# CH583SFR register map
Vendor: WCH Ltd.; Series: CH58x; File version: 1.1
CPU: RISC-V r0p0, little endian, no MPU, no FPU, 2 interrupt priority bits
Registers are 8-bit, read-write, reset 0x0 unless marked. A register's access mark holds for its fields unless they carry their own. Offsets are from the block's base; [hi:lo] are bit positions.

## GPIOB — System Control Register
Base 0x40001000
0x92 INT_EN 16-bit — RW, GPIO PB interrupt enable
  [15:0] INT_EN — GPIO PB interrupt enable
0x96 INT_MODE 16-bit — RW, GPIO PB interrupt mode: 0=level action, 1=edge action
  [15:0] INT_MODE — GPIO PB interrupt mode
0x9E INT_IF 16-bit — RW1, GPIO PB interrupt flag
  [15:0] INT_IF — GPIO PB interrupt flag
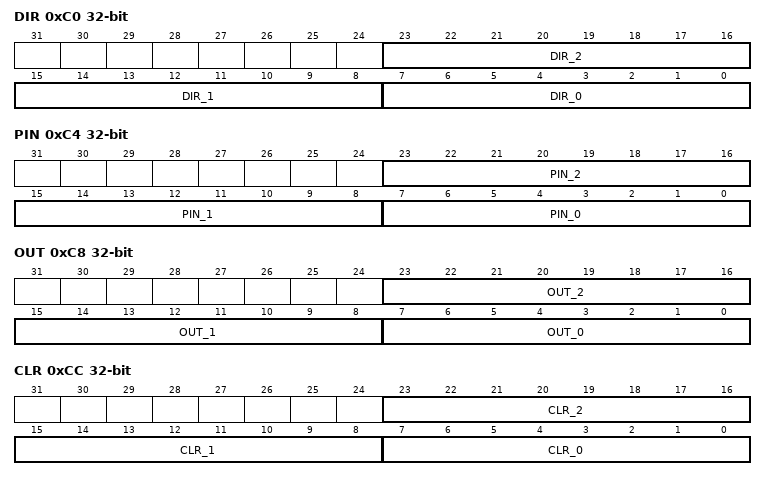
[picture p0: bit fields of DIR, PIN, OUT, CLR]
0xC0 DIR 32-bit — RW, GPIO PB I/O direction: 0=in, 1=out
  [23:16] DIR_2 — GPIO PB I/O direction byte 2
  [15:8] DIR_1 — GPIO PB I/O direction byte 1
  [7:0] DIR_0 — GPIO PB I/O direction byte 0
0xC4 PIN 32-bit ro — RO, GPIO PB input
  [23:16] PIN_2 — GPIO PB input byte 2
  [15:8] PIN_1 — GPIO PB input byte 1
  [7:0] PIN_0 — GPIO PB input byte 0
0xC8 OUT 32-bit — RW, GPIO PB output
  [23:16] OUT_2 — GPIO PB output byte 2
  [15:8] OUT_1 — GPIO PB output byte 1
  [7:0] OUT_0 — GPIO PB output byte 0
0xCC CLR 32-bit — WZ, GPIO PB clear output: 0=keep, 1=clear
  [23:16] CLR_2 — GPIO PB clear output byte 2
  [15:8] CLR_1 — GPIO PB clear output byte 1
  [7:0] CLR_0 — GPIO PB clear output byte 0
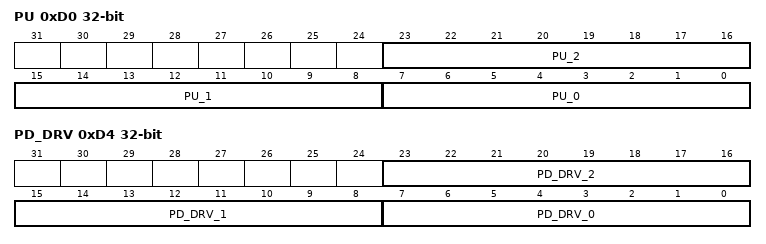
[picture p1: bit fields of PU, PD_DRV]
0xD0 PU 32-bit — RW, GPIO PB pullup resistance enable
  [23:16] PU_2 — GPIO PB pullup resistance enable byte 2
  [15:8] PU_1 — GPIO PB pullup resistance enable byte 1
  [7:0] PU_0 — GPIO PB pullup resistance enable byte 0
0xD4 PD_DRV 32-bit — RW, PB pulldown for input or PB driving capability for output
  [23:16] PD_DRV_2 — PB pulldown for input or PB driving capability for output byte 0
  [15:8] PD_DRV_1 — PB pulldown for input or PB driving capability for output byte 0
  [7:0] PD_DRV_0 — PB pulldown for input or PB driving capability for output byte 0

## TMR0 — Timer0 register
Base 0x40002000
0x00 CTRL_MOD reset 0x2 — RW, TMR0 mode control
  [7:6] PWM_REPEAT — RW, timer PWM repeat mode: 00=1, 01=4, 10=8, 11-16
  [7:6] CAP_EDGE — RW, timer capture edge mode: 00=disable, 01=edge change, 10=fall to fall, 11-rise to rise
  [4] OUT_POLAR — RW, timer PWM output polarity: 0=default low and high action, 1=default high and low action
  [4] CAP_COUNT — RW, count sub-mode if RB_TMR_MODE_IN=1: 0=capture, 1=count
  [3] OUT_EN — RW, timer output enable
  [2] COUNT_EN — RW, timer count enable
  [1] ALL_CLEAR — RW, force clear timer FIFO and count
  [0] MODE_IN — RW, timer in mode: 0=timer/PWM, 1=capture/count
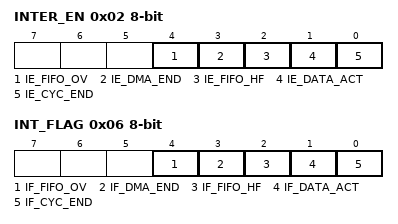
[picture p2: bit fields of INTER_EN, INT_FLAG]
0x02 INTER_EN — RW, TMR0 interrupt enable
  [4] IE_FIFO_OV — RW, enable interrupt for timer FIFO overflow
  [3] IE_DMA_END — RW, enable interrupt for timer1/2 DMA completion
  [2] IE_FIFO_HF — RW, enable interrupt for timer FIFO half (capture fifo >=4 or PWM fifo less than 3)
  [1] IE_DATA_ACT — RW, enable interrupt for timer capture input action or PWM trigger
  [0] IE_CYC_END — RW, enable interrupt for timer capture count timeout or PWM cycle end
0x06 INT_FLAG — RW1, TMR0 interrupt flag
  [4] IF_FIFO_OV — RW1, interrupt flag for timer FIFO overflow
  [3] IF_DMA_END — RW1, interrupt flag for timer1/2 DMA completion
  [2] IF_FIFO_HF — RW1, interrupt flag for timer FIFO half (capture fifo >=4 or PWM fifo less than 3
  [1] IF_DATA_ACT — RW1, interrupt flag for timer capture input action or PWM trigger
  [0] IF_CYC_END — RW1, interrupt flag for timer capture count timeout or PWM cycle end
0x07 FIFO_COUNT ro (reset mask 0xF0) — RO, TMR0 FIFO count status
  [7:0] FIFO_COUNT — RW1,TMR0 FIFO count status
0x08 COUNT 32-bit ro — RO, TMR0 current count
  [31:0] COUNT — RW1,TMR0 current count
0x0C CNT_END 32-bit — RW, TMR0 end count value, only low 26 bit
  [31:0] CNT_END — RW1,TMR0 end count value
0x10 FIFO 32-bit ro — RO/WO, TMR0 FIFO register, only low 26 bit
  [31:0] FIFO — RW1,TMR0 FIFO register

## TMR1 — Timer1 register
Base 0x40002400
Registers as TMR0 (with TMR0 read as TMR1); these are added or differ:
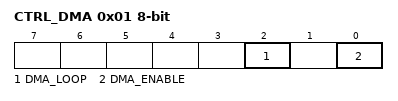
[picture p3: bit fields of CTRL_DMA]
0x01 CTRL_DMA — RW, TMR1 DMA control
  [2] DMA_LOOP — RW, timer1/2 DMA address loop enable
  [0] DMA_ENABLE — RW, timer1/2 DMA enable
0x07 FIFO_COUNT ro (reset mask 0xF0) — RO, TMR1 FIFO count status
  [7:0] FIFO_COUNT — RW1, TMR1 FIFO count status
0x0C CNT_END 32-bit — RW, TMR1 end count value, only low 26 bit
  [31:0] CNT_END — RW1,TMR1 end count value,
0x10 FIFO 32-bit ro — RO, TMR1 FIFO register, only low 26 bit
  [31:0] FIFO — RW1,TMR1 FIFO register
0x14 DMA_NOW 16-bit ro — RO, TMR1 DMA current address
  [15:0] DMA_NOW — RW1,TMR1 FIFO register
0x18 DMA_BEG 16-bit — RW, TMR1 DMA begin address
  [15:0] DMA_BEG — RW1,TMR1 FIFO register
0x1C DMA_END 16-bit — RW, TMR1 DMA end address
  [15:0] DMA_END — RW1,TMR1 FIFO register

## TMR3 — Timer3 register
Base 0x40002C00
Registers as TMR0 (with TMR0 read as TMR3); these are added or differ:
0x07 FIFO_COUNT ro (reset mask 0xF0) — RO, TMR3 FIFO count status
  [7:0] FIFO_COUNT — R0, TMR3 FIFO count status
0x08 COUNT 32-bit ro — RO, TMR3 current count
  [31:0] COUNT — R0, TMR3 current count
0x0C CNT_END 32-bit — RW, TMR3 end count value, only low 26 bit
0x10 FIFO 32-bit — RO/WO, TMR3 FIFO register, only low 26 bit
